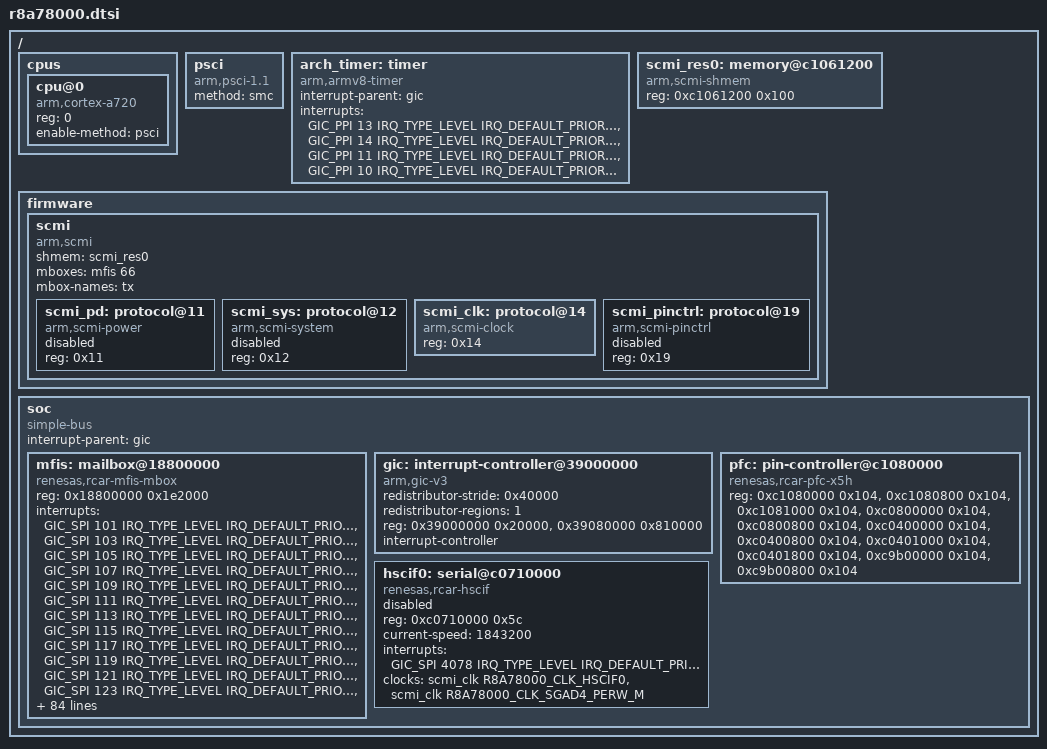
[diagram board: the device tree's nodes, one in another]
/*
 * Copyright (c) 2026 Renesas Electronics Corporation
 *
 * SPDX-License-Identifier: Apache-2.0
 */

/dts-v1/;

#include <arm64/armv9-a.dtsi>
#include <zephyr/dt-bindings/interrupt-controller/arm-gic.h>
#include <zephyr/dt-bindings/clock/r8a78000_cpg_mssr.h>

/ {
	cpus {
		#address-cells = <1>;
		#size-cells = <0>;

		cpu@0 {
			compatible = "arm,cortex-a720";
			reg = <0>;
			device_type = "cpu";
			enable-method = "psci";
		};
	};

	psci {
		compatible = "arm,psci-1.1";
		method = "smc";
	};

	arch_timer: timer {
		compatible = "arm,armv8-timer";
		interrupt-parent = <&gic>;
		interrupts = <GIC_PPI 13 IRQ_TYPE_LEVEL IRQ_DEFAULT_PRIORITY>,
			     <GIC_PPI 14 IRQ_TYPE_LEVEL IRQ_DEFAULT_PRIORITY>,
			     <GIC_PPI 11 IRQ_TYPE_LEVEL IRQ_DEFAULT_PRIORITY>,
			     <GIC_PPI 10 IRQ_TYPE_LEVEL IRQ_DEFAULT_PRIORITY>;
	};

	scmi_res0: memory@c1061200 {
		compatible = "arm,scmi-shmem";
		reg = <0xc1061200 0x100>;
	};

	firmware {
		scmi {
			#address-cells = <1>;
			#size-cells = <0>;

			compatible = "arm,scmi";
			shmem = <&scmi_res0>;
			mboxes = <&mfis 66>;
			mbox-names = "tx";

			scmi_pd: protocol@11 {
				compatible = "arm,scmi-power";
				reg = <0x11>;
				#power-domain-cells = <1>;
				status = "disabled";
			};

			scmi_sys: protocol@12 {
				compatible = "arm,scmi-system";
				reg = <0x12>;
				status = "disabled";
			};

			scmi_clk: protocol@14 {
				compatible = "arm,scmi-clock";
				reg = <0x14>;
				#clock-cells = <1>;
			};

			scmi_pinctrl: protocol@19 {
				compatible = "arm,scmi-pinctrl";
				reg = <0x19>;
				status = "disabled";
			};
		};
	};

	soc {
		compatible = "simple-bus";
		interrupt-parent = <&gic>;
		ranges;

		mfis: mailbox@18800000 {
			compatible = "renesas,rcar-mfis-mbox";
			reg = <0x18800000 0x1e2000>;
			#mbox-cells = <1>;
			interrupts = <GIC_SPI 101 IRQ_TYPE_LEVEL IRQ_DEFAULT_PRIORITY>, /* Common */
				     <GIC_SPI 103 IRQ_TYPE_LEVEL IRQ_DEFAULT_PRIORITY>,
				     <GIC_SPI 105 IRQ_TYPE_LEVEL IRQ_DEFAULT_PRIORITY>,
				     <GIC_SPI 107 IRQ_TYPE_LEVEL IRQ_DEFAULT_PRIORITY>,
				     <GIC_SPI 109 IRQ_TYPE_LEVEL IRQ_DEFAULT_PRIORITY>,
				     <GIC_SPI 111 IRQ_TYPE_LEVEL IRQ_DEFAULT_PRIORITY>,
				     <GIC_SPI 113 IRQ_TYPE_LEVEL IRQ_DEFAULT_PRIORITY>,
				     <GIC_SPI 115 IRQ_TYPE_LEVEL IRQ_DEFAULT_PRIORITY>,
				     <GIC_SPI 117 IRQ_TYPE_LEVEL IRQ_DEFAULT_PRIORITY>,
				     <GIC_SPI 119 IRQ_TYPE_LEVEL IRQ_DEFAULT_PRIORITY>,
				     <GIC_SPI 121 IRQ_TYPE_LEVEL IRQ_DEFAULT_PRIORITY>,
				     <GIC_SPI 123 IRQ_TYPE_LEVEL IRQ_DEFAULT_PRIORITY>,
				     <GIC_SPI 125 IRQ_TYPE_LEVEL IRQ_DEFAULT_PRIORITY>,
				     <GIC_SPI 127 IRQ_TYPE_LEVEL IRQ_DEFAULT_PRIORITY>,
				     <GIC_SPI 129 IRQ_TYPE_LEVEL IRQ_DEFAULT_PRIORITY>,
				     <GIC_SPI 131 IRQ_TYPE_LEVEL IRQ_DEFAULT_PRIORITY>,
				     <GIC_SPI 133 IRQ_TYPE_LEVEL IRQ_DEFAULT_PRIORITY>,
				     <GIC_SPI 135 IRQ_TYPE_LEVEL IRQ_DEFAULT_PRIORITY>,
				     <GIC_SPI 137 IRQ_TYPE_LEVEL IRQ_DEFAULT_PRIORITY>,
				     <GIC_SPI 139 IRQ_TYPE_LEVEL IRQ_DEFAULT_PRIORITY>,
				     <GIC_SPI 141 IRQ_TYPE_LEVEL IRQ_DEFAULT_PRIORITY>,
				     <GIC_SPI 143 IRQ_TYPE_LEVEL IRQ_DEFAULT_PRIORITY>,
				     <GIC_SPI 145 IRQ_TYPE_LEVEL IRQ_DEFAULT_PRIORITY>,
				     <GIC_SPI 147 IRQ_TYPE_LEVEL IRQ_DEFAULT_PRIORITY>,
				     <GIC_SPI 149 IRQ_TYPE_LEVEL IRQ_DEFAULT_PRIORITY>,
				     <GIC_SPI 151 IRQ_TYPE_LEVEL IRQ_DEFAULT_PRIORITY>,
				     <GIC_SPI 153 IRQ_TYPE_LEVEL IRQ_DEFAULT_PRIORITY>,
				     <GIC_SPI 155 IRQ_TYPE_LEVEL IRQ_DEFAULT_PRIORITY>,
				     <GIC_SPI 157 IRQ_TYPE_LEVEL IRQ_DEFAULT_PRIORITY>,
				     <GIC_SPI 159 IRQ_TYPE_LEVEL IRQ_DEFAULT_PRIORITY>,
				     <GIC_SPI 161 IRQ_TYPE_LEVEL IRQ_DEFAULT_PRIORITY>,
				     <GIC_SPI 163 IRQ_TYPE_LEVEL IRQ_DEFAULT_PRIORITY>,
				     <GIC_SPI 165 IRQ_TYPE_LEVEL IRQ_DEFAULT_PRIORITY>,
				     <GIC_SPI 167 IRQ_TYPE_LEVEL IRQ_DEFAULT_PRIORITY>,
				     <GIC_SPI 169 IRQ_TYPE_LEVEL IRQ_DEFAULT_PRIORITY>,
				     <GIC_SPI 171 IRQ_TYPE_LEVEL IRQ_DEFAULT_PRIORITY>,
				     <GIC_SPI 173 IRQ_TYPE_LEVEL IRQ_DEFAULT_PRIORITY>,
				     <GIC_SPI 175 IRQ_TYPE_LEVEL IRQ_DEFAULT_PRIORITY>,
				     <GIC_SPI 177 IRQ_TYPE_LEVEL IRQ_DEFAULT_PRIORITY>,
				     <GIC_SPI 179 IRQ_TYPE_LEVEL IRQ_DEFAULT_PRIORITY>,
				     <GIC_SPI 181 IRQ_TYPE_LEVEL IRQ_DEFAULT_PRIORITY>,
				     <GIC_SPI 183 IRQ_TYPE_LEVEL IRQ_DEFAULT_PRIORITY>,
				     <GIC_SPI 185 IRQ_TYPE_LEVEL IRQ_DEFAULT_PRIORITY>,
				     <GIC_SPI 187 IRQ_TYPE_LEVEL IRQ_DEFAULT_PRIORITY>,
				     <GIC_SPI 189 IRQ_TYPE_LEVEL IRQ_DEFAULT_PRIORITY>,
				     <GIC_SPI 191 IRQ_TYPE_LEVEL IRQ_DEFAULT_PRIORITY>,
				     <GIC_SPI 193 IRQ_TYPE_LEVEL IRQ_DEFAULT_PRIORITY>,
				     <GIC_SPI 195 IRQ_TYPE_LEVEL IRQ_DEFAULT_PRIORITY>,
				     <GIC_SPI 197 IRQ_TYPE_LEVEL IRQ_DEFAULT_PRIORITY>,
				     <GIC_SPI 199 IRQ_TYPE_LEVEL IRQ_DEFAULT_PRIORITY>,
				     <GIC_SPI 201 IRQ_TYPE_LEVEL IRQ_DEFAULT_PRIORITY>,
				     <GIC_SPI 203 IRQ_TYPE_LEVEL IRQ_DEFAULT_PRIORITY>,
				     <GIC_SPI 205 IRQ_TYPE_LEVEL IRQ_DEFAULT_PRIORITY>,
				     <GIC_SPI 207 IRQ_TYPE_LEVEL IRQ_DEFAULT_PRIORITY>,
				     <GIC_SPI 209 IRQ_TYPE_LEVEL IRQ_DEFAULT_PRIORITY>,
				     <GIC_SPI 211 IRQ_TYPE_LEVEL IRQ_DEFAULT_PRIORITY>,
				     <GIC_SPI 213 IRQ_TYPE_LEVEL IRQ_DEFAULT_PRIORITY>,
				     <GIC_SPI 215 IRQ_TYPE_LEVEL IRQ_DEFAULT_PRIORITY>,
				     <GIC_SPI 217 IRQ_TYPE_LEVEL IRQ_DEFAULT_PRIORITY>,
				     <GIC_SPI 219 IRQ_TYPE_LEVEL IRQ_DEFAULT_PRIORITY>,
				     <GIC_SPI 221 IRQ_TYPE_LEVEL IRQ_DEFAULT_PRIORITY>,
				     <GIC_SPI 223 IRQ_TYPE_LEVEL IRQ_DEFAULT_PRIORITY>,
				     <GIC_SPI 225 IRQ_TYPE_LEVEL IRQ_DEFAULT_PRIORITY>,
				     <GIC_SPI 227 IRQ_TYPE_LEVEL IRQ_DEFAULT_PRIORITY>,
				     /* SCP to AP */
				     <GIC_SPI 4360 IRQ_TYPE_LEVEL IRQ_DEFAULT_PRIORITY>,
				     <GIC_SPI 4361 IRQ_TYPE_LEVEL IRQ_DEFAULT_PRIORITY>,
				     <GIC_SPI 4362 IRQ_TYPE_LEVEL IRQ_DEFAULT_PRIORITY>,
				     <GIC_SPI 4363 IRQ_TYPE_LEVEL IRQ_DEFAULT_PRIORITY>,
				     <GIC_SPI 4364 IRQ_TYPE_LEVEL IRQ_DEFAULT_PRIORITY>,
				     <GIC_SPI 4365 IRQ_TYPE_LEVEL IRQ_DEFAULT_PRIORITY>,
				     <GIC_SPI 4366 IRQ_TYPE_LEVEL IRQ_DEFAULT_PRIORITY>,
				     <GIC_SPI 4367 IRQ_TYPE_LEVEL IRQ_DEFAULT_PRIORITY>,
				     <GIC_SPI 4368 IRQ_TYPE_LEVEL IRQ_DEFAULT_PRIORITY>,
				     <GIC_SPI 4369 IRQ_TYPE_LEVEL IRQ_DEFAULT_PRIORITY>,
				     <GIC_SPI 4370 IRQ_TYPE_LEVEL IRQ_DEFAULT_PRIORITY>,
				     <GIC_SPI 4371 IRQ_TYPE_LEVEL IRQ_DEFAULT_PRIORITY>,
				     <GIC_SPI 4372 IRQ_TYPE_LEVEL IRQ_DEFAULT_PRIORITY>,
				     <GIC_SPI 4373 IRQ_TYPE_LEVEL IRQ_DEFAULT_PRIORITY>,
				     <GIC_SPI 4374 IRQ_TYPE_LEVEL IRQ_DEFAULT_PRIORITY>,
				     <GIC_SPI 4375 IRQ_TYPE_LEVEL IRQ_DEFAULT_PRIORITY>,
				     <GIC_SPI 4376 IRQ_TYPE_LEVEL IRQ_DEFAULT_PRIORITY>,
				     <GIC_SPI 4377 IRQ_TYPE_LEVEL IRQ_DEFAULT_PRIORITY>,
				     <GIC_SPI 4378 IRQ_TYPE_LEVEL IRQ_DEFAULT_PRIORITY>,
				     <GIC_SPI 4379 IRQ_TYPE_LEVEL IRQ_DEFAULT_PRIORITY>,
				     <GIC_SPI 4380 IRQ_TYPE_LEVEL IRQ_DEFAULT_PRIORITY>,
				     <GIC_SPI 4381 IRQ_TYPE_LEVEL IRQ_DEFAULT_PRIORITY>,
				     <GIC_SPI 4382 IRQ_TYPE_LEVEL IRQ_DEFAULT_PRIORITY>,
				     <GIC_SPI 4383 IRQ_TYPE_LEVEL IRQ_DEFAULT_PRIORITY>,
				     <GIC_SPI 4384 IRQ_TYPE_LEVEL IRQ_DEFAULT_PRIORITY>,
				     <GIC_SPI 4385 IRQ_TYPE_LEVEL IRQ_DEFAULT_PRIORITY>,
				     <GIC_SPI 4386 IRQ_TYPE_LEVEL IRQ_DEFAULT_PRIORITY>,
				     <GIC_SPI 4387 IRQ_TYPE_LEVEL IRQ_DEFAULT_PRIORITY>,
				     <GIC_SPI 4388 IRQ_TYPE_LEVEL IRQ_DEFAULT_PRIORITY>,
				     <GIC_SPI 4389 IRQ_TYPE_LEVEL IRQ_DEFAULT_PRIORITY>,
				     <GIC_SPI 4390 IRQ_TYPE_LEVEL IRQ_DEFAULT_PRIORITY>,
				     <GIC_SPI 4391 IRQ_TYPE_LEVEL IRQ_DEFAULT_PRIORITY>;
		};

		gic: interrupt-controller@39000000 {
			compatible = "arm,gic-v3", "arm,gic";
			redistributor-stride = <0x40000>; /* 256kB stride */
			redistributor-regions = <1>;
			reg = <0x39000000 0x20000>, /* GICD */
			      <0x39080000 0x810000>; /* GICR */
			interrupt-controller;
			#interrupt-cells = <4>;
			status = "okay";
		};

		pfc: pin-controller@c1080000 {
			compatible = "renesas,rcar-pfc-x5h";
			reg = <0xc1080000 0x104>, <0xc1080800 0x104>,
			      <0xc1081000 0x104>, <0xc0800000 0x104>,
			      <0xc0800800 0x104>, <0xc0400000 0x104>,
			      <0xc0400800 0x104>, <0xc0401000 0x104>,
			      <0xc0401800 0x104>, <0xc9b00000 0x104>,
			      <0xc9b00800 0x104>;
		};

		hscif0: serial@c0710000 {
			compatible = "renesas,rcar-hscif";
			reg = <0xc0710000 0x5c>;
			current-speed = <1843200>;
			interrupts = <GIC_SPI 4078 IRQ_TYPE_LEVEL IRQ_DEFAULT_PRIORITY>;
			clocks = <&scmi_clk R8A78000_CLK_HSCIF0>, /* Mod clk */
				 <&scmi_clk R8A78000_CLK_SGAD4_PERW_M>; /* Bus clk */
			status = "disabled";
		};
	};
};
